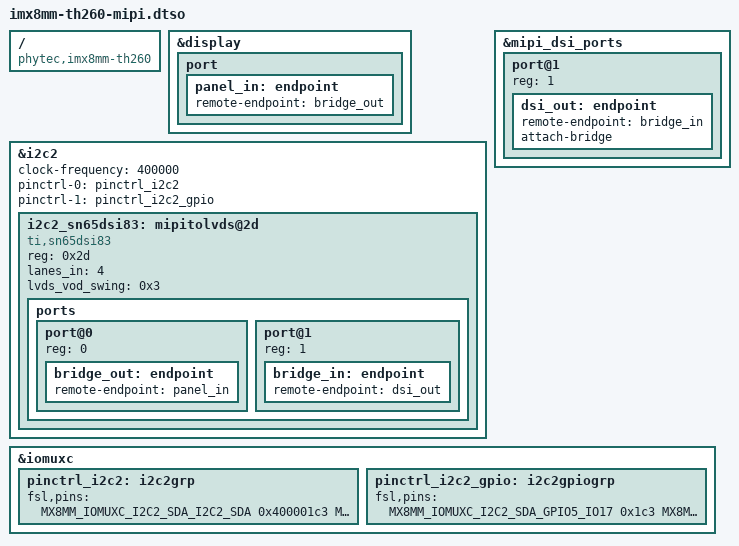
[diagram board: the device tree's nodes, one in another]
// SPDX-License-Identifier: GPL-2.0
/*
 * Copyright (C) 2022 PHYTEC Messtechnik GmbH
 * Author: Teresa Remmet <t.remmet@phytec.de>
 *
 * Overlay for DUT SoMs where no MIPI2LVDS converter is on SoM.
 * So the converter on the TH260 has to be used.
 */

/dts-v1/;
/plugin/;

#include "../imx8mm-pinfunc.h"

/ {
	compatible = "phytec,imx8mm-th260";
};

&display {
	port {
		panel_in: endpoint {
			remote-endpoint = <&bridge_out>;
		};
	};
};

&i2c2 {
	clock-frequency = <400000>;
	pinctrl-names = "default", "gpio";
	pinctrl-0 = <&pinctrl_i2c2>;
	pinctrl-1 = <&pinctrl_i2c2_gpio>;
	status = "okay";

	#address-cells = <1>;
	#size-cells = <0>;

	i2c2_sn65dsi83: mipitolvds@2d {
		compatible = "ti,sn65dsi83";
		reg = <0x2d>;
		lanes_in = <4>;
		lvds_vod_swing = <0x3>;

		ports {
			#address-cells = <1>;
			#size-cells = <0>;

			port@0 {
				reg = <0>;
				bridge_out: endpoint {
					remote-endpoint = <&panel_in>;
				};
			};

			port@1 {
				reg = <1>;
				bridge_in: endpoint {
					remote-endpoint = <&dsi_out>;
				};
                        };
                };
        };
};

&mipi_dsi_ports {
	#address-cells = <0x1>;
	#size-cells = <0x0>;

	port@1 {
		reg = <1>;
		dsi_out: endpoint {
			remote-endpoint = <&bridge_in>;
			attach-bridge;
		};
	};
};

&iomuxc {
	pinctrl_i2c2: i2c2grp {
		fsl,pins = <
			MX8MM_IOMUXC_I2C2_SDA_I2C2_SDA		0x400001c3
			MX8MM_IOMUXC_I2C2_SCL_I2C2_SCL		0x400001c3
		>;
	};

	pinctrl_i2c2_gpio: i2c2gpiogrp {
		fsl,pins = <
			MX8MM_IOMUXC_I2C2_SDA_GPIO5_IO17	0x1c3
			MX8MM_IOMUXC_I2C2_SCL_GPIO5_IO16	0x1c3
		>;
	};
};
